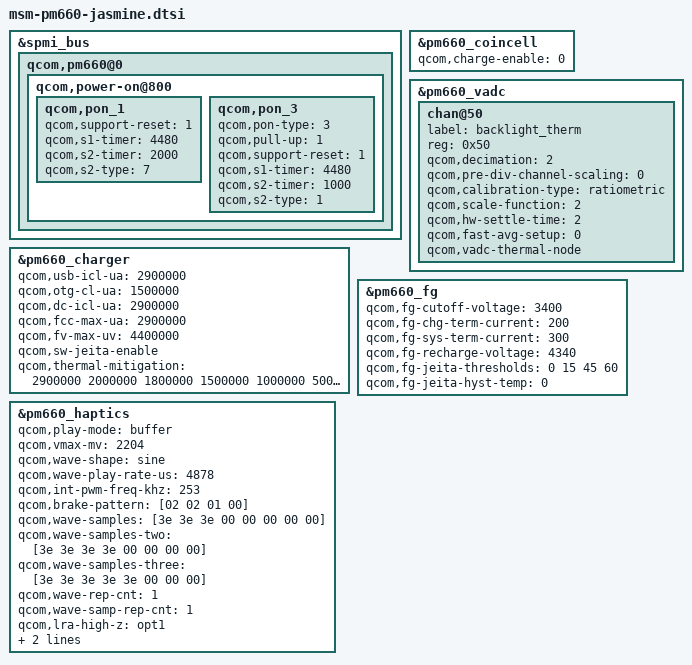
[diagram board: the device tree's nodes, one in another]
&spmi_bus {
	qcom,pm660@0 {
		qcom,power-on@800 {
			qcom,pon_1 {
				qcom,support-reset = <1>;
				qcom,s1-timer = <4480>;
				qcom,s2-timer = <2000>;
				qcom,s2-type = <7>;
			};

			qcom,pon_3 {
				qcom,pon-type = <3>;
				qcom,pull-up = <1>;
				qcom,support-reset = <1>;
				qcom,s1-timer = <4480>;
				qcom,s2-timer = <1000>;
				qcom,s2-type = <1>;
			};
		};
	};
};

&pm660_coincell {
	qcom,charge-enable = <0>;
};

&pm660_vadc {
	chan@50 {
		label = "backlight_therm";
		reg = <0x50>;
		qcom,decimation = <2>;
		qcom,pre-div-channel-scaling = <0>;
		qcom,calibration-type = "ratiometric";
		qcom,scale-function = <2>;
		qcom,hw-settle-time = <2>;
		qcom,fast-avg-setup = <0>;
		qcom,vadc-thermal-node;
	};
};

&pm660_charger {
	qcom,usb-icl-ua = <2900000>;
	qcom,otg-cl-ua = <1500000>;
	qcom,dc-icl-ua = <2900000>;
	qcom,fcc-max-ua = <2900000>;
	qcom,fv-max-uv  = <4400000>;
	qcom,sw-jeita-enable;

	qcom,thermal-mitigation
			= <2900000 2000000 1800000 1500000 1000000 500000 100000>;
};

&pm660_fg {
	qcom,fg-cutoff-voltage = <3400>;
	qcom,fg-chg-term-current = <200>;
	qcom,fg-sys-term-current = <300>;
	qcom,fg-recharge-voltage = <4340>;
	qcom,fg-jeita-thresholds = <0 15 45 60>;
	qcom,fg-jeita-hyst-temp = <0>;
};

&pm660_haptics {
	qcom,play-mode = "buffer";
	qcom,vmax-mv = <2204>;
	qcom,wave-shape = "sine";
	qcom,wave-play-rate-us = <4878>;
	qcom,int-pwm-freq-khz = <253>;
	qcom,brake-pattern = [02 02 01 00];
	qcom,wave-samples = [3e 3e 3e 00 00 00 00 00];
	qcom,wave-samples-two = [3e 3e 3e 3e 00 00 00 00];
	qcom,wave-samples-three = [3e 3e 3e 3e 3e 00 00 00];
	qcom,wave-rep-cnt = <1>;
	qcom,wave-samp-rep-cnt = <1>;
	qcom,lra-high-z = "opt1";
	qcom,lra-auto-res-mode = "none";
	/delete-property/ qcom,correct-lra-drive-freq;
	qcom,lra-hw-auto-resonance;
};
